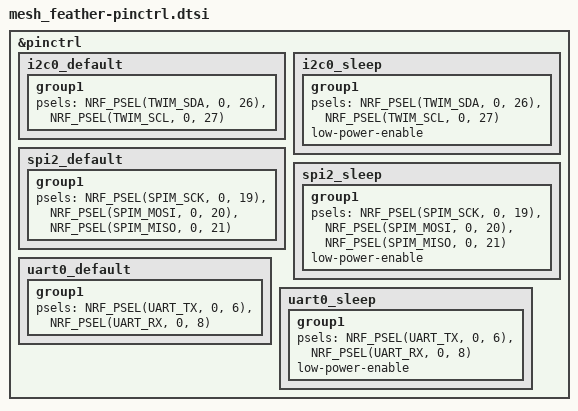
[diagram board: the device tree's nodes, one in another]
/*
 * Copyright (c) 2022 Nordic Semiconductor
 * SPDX-License-Identifier: Apache-2.0
 */

&pinctrl {
	i2c0_default: i2c0_default {
		group1 {
			psels = <NRF_PSEL(TWIM_SDA, 0, 26)>,
				<NRF_PSEL(TWIM_SCL, 0, 27)>;
		};
	};

	i2c0_sleep: i2c0_sleep {
		group1 {
			psels = <NRF_PSEL(TWIM_SDA, 0, 26)>,
				<NRF_PSEL(TWIM_SCL, 0, 27)>;
			low-power-enable;
		};
	};

	spi2_default: spi2_default {
		group1 {
			psels = <NRF_PSEL(SPIM_SCK, 0, 19)>,
				<NRF_PSEL(SPIM_MOSI, 0, 20)>,
				<NRF_PSEL(SPIM_MISO, 0, 21)>;
		};
	};

	spi2_sleep: spi2_sleep {
		group1 {
			psels = <NRF_PSEL(SPIM_SCK, 0, 19)>,
				<NRF_PSEL(SPIM_MOSI, 0, 20)>,
				<NRF_PSEL(SPIM_MISO, 0, 21)>;
			low-power-enable;
		};
	};

	uart0_default: uart0_default {
		group1 {
			psels = <NRF_PSEL(UART_TX, 0, 6)>,
				<NRF_PSEL(UART_RX, 0, 8)>;
		};
	};

	uart0_sleep: uart0_sleep {
		group1 {
			psels = <NRF_PSEL(UART_TX, 0, 6)>,
				<NRF_PSEL(UART_RX, 0, 8)>;
			low-power-enable;
		};
	};

};
